# STM32H5F4 register map
File version: 1.0
CPU: CM33 r0p0, little endian, MPU, FPU, 4 interrupt priority bits
Registers are 32-bit, read-write, reset 0x0 unless marked. A register's access mark holds for its fields unless they carry their own. Offsets are from the block's base; [hi:lo] are bit positions; 'fields as' and 'values as' point back to an identical list.

## SAI1 — SAI1 register block
Base 0x40015400
Same registers: SAI2 0x40015800, SAI1_S 0x50015400, SAI2_S 0x50015800
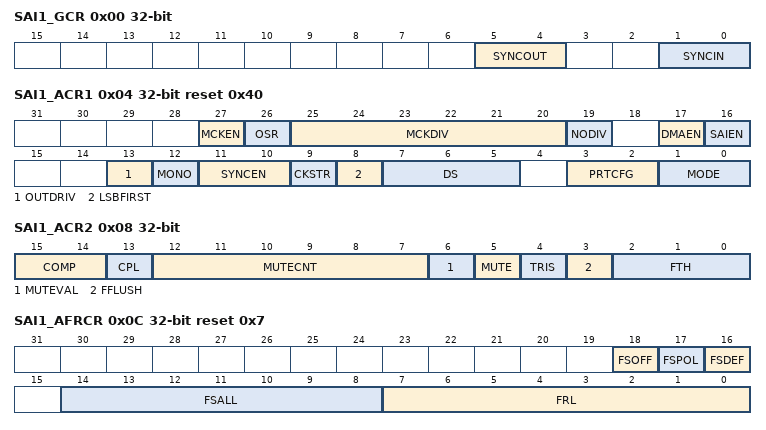
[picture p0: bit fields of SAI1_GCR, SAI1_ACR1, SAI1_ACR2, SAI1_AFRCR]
0x00 SAI1_GCR — SAI global configuration register
  [5:4] SYNCOUT — Synchronization outputs
    0=No synchronization output signals; 1=Block A used for further synchronization for others SAI; 2=Block B used for further synchronization for others SAI
  [1:0] SYNCIN — Synchronization inputs
0x04 SAI1_ACR1 reset 0x40 — SAI configuration register 1
  [27] MCKEN — Master clock generation enable
    0=The master clock is not generated; 1=The master clock is generated independently of SAIEN bit
  [26] OSR — Oversampling ratio for master clock
    0=Master clock frequency = Fless thansub>FSless than/sub> x 256; 1=Master clock frequency = Fless thansub>FSless than/sub> x 512
  [25:20] MCKDIV — Master clock divider
    0=Divides by 1 the kernel clock input (sai_x_ker_ck)
  [19] NODIV — No divider
    0=the ratio between the Master clock generator and frame synchronization is fixed to 256 or 512; 1=the ratio between the Master clock generator and frame synchronization depends on FRL[7:0]
  [17] DMAEN — DMA enable
    0=DMA disabled; 1=DMA enabled
  [16] SAIEN — Audio block enable
    0=SAI audio block disabled; 1=SAI audio block enabled
  [13] OUTDRIV — Output drive
    0=Audio block output driven when SAIEN is set; 1=Audio block output driven immediately after the setting of this bit
  [12] MONO — Mono mode
    0=Stereo mode; 1=Mono mode
  [11:10] SYNCEN — Synchronization enable
    0=audio subblock in asynchronous mode; 1=audio subblock is synchronous with the other internal audio subblock; 2=audio subblock is synchronous with an external SAI embedded peripheral
  [9] CKSTR — Clock strobing edge
    0=Signals generated by the SAI change on SCK rising edge, while signals received by the SAI are sampled on the SCK falling edge; 1=Signals generated by the SAI change on SCK falling edge, while signals received by the SAI are sampled on the SCK rising edge
  [8] LSBFIRST — Least significant bit first
    0=Data are transferred with MSB first; 1=Data are transferred with LSB first
  [7:5] DS — Data size
    2=8 bits; 3=10 bits; 4=16 bits; 5=20 bits; 6=24 bits; 7=32 bits
  [3:2] PRTCFG — Protocol configuration
    0=Free protocol; 1=SPDIF protocol; 2=AC'97 protocol
  [1:0] MODE — SAIx audio block mode
    0=Master transmitter; 1=Master receiver; 2=Slave transmitter; 3=Slave receiver
0x08 SAI1_ACR2 — SAI configuration register 2
  [15:14] COMP — Companding mode.
    0=No companding algorithm; 2=u-Law algorithm; 3=A-Law algorithm
  [13] CPL — Complement bit.
    0=1's complement representation; 1=2's complement representation
  [12:7] MUTECNT — Mute counter.
  [6] MUTEVAL — Mute value.
    0=Bit value 0 is sent during the mute mode; 1=Last values are sent during the mute mode
  [5] MUTE
    0=No mute mode; 1=Mute mode enabled
  [4] TRIS — Tristate management on data line.
    0=SD output line is still driven by the SAI when a slot is inactive; 1=SD output line is released (HI-Z) at the end of the last data bit of the last active slot if the next one is inactive
  [3] FFLUSH wo — FIFO flush.
    0=No FIFO flush; 1=FIFO flush
  [2:0] FTH — FIFO threshold.
    0=FIFO empty; 1=1/4 FIFO; 2=half FIFO; 3=3/4 FIFO; 4=FIFO full
0x0C SAI1_AFRCR reset 0x7 — SAI frame configuration register
  [18] FSOFF — Frame synchronization offset.
    0=FS is asserted on the first bit of the slot 0; 1=FS is asserted one bit before the first bit of the slot 0
  [17] FSPOL — Frame synchronization polarity.
    0=FS is active low (falling edge); 1=FS is active high (rising edge)
  [16] FSDEF ro — Frame synchronization definition.
    0=FS signal is a start frame signal; 1=FS signal is a start of frame signal + channel side identification
  [14:8] FSALL — Frame synchronization active level length.
  [7:0] FRL — Frame length.
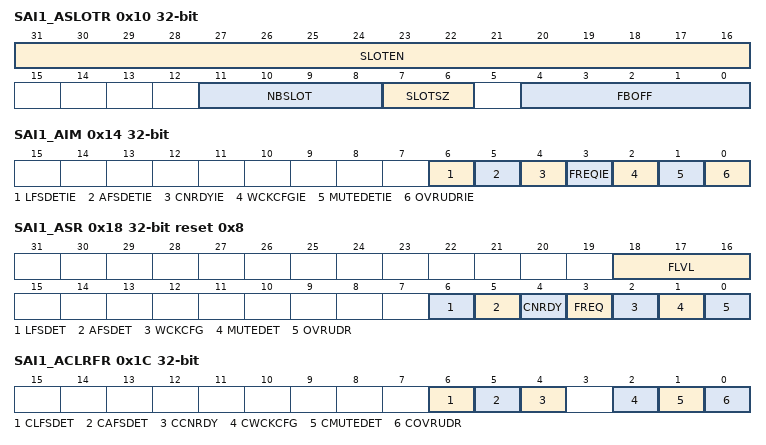
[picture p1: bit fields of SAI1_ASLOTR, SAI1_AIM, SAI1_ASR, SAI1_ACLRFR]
0x10 SAI1_ASLOTR — SAI slot register
  [31:16] SLOTEN — Slot enable.
    0=Inactive slot; 1=Active slot
  [11:8] NBSLOT — Number of slots in an audio frame.
  [7:6] SLOTSZ — Slot size
    0=The slot size is equivalent to the data size (specified in DS[3:0] in the SAI_xCR1 register); 1=16-bit; 2=32-bit
  [4:0] FBOFF — First bit offset
0x14 SAI1_AIM — SAI interrupt mask register
  [all] fields
    0=Interrupt is disabled; 1=Interrupt is enabled
  [6] LFSDETIE — Late frame synchronization detection interrupt enable.
  [5] AFSDETIE — Anticipated frame synchronization detection interrupt enable.
  [4] CNRDYIE — Codec not ready interrupt enable (AC'97).
  [3] FREQIE — FIFO request interrupt enable.
  [2] WCKCFGIE — Wrong clock configuration interrupt enable.
  [1] MUTEDETIE — Mute detection interrupt enable.
  [0] OVRUDRIE — Overrun/underrun interrupt enable.
0x18 SAI1_ASR ro reset 0x8 — SAI status register
  [18:16] FLVL — FIFO level threshold.
    0=FIFO empty (transmitter and receiver modes); 1=FIFO less than or equal 1/4 but not empty (transmitter mode), FIFO less than 1/4 but not empty (receiver mode); 2=1/4 less than FIFO less than or equal half (transmitter mode), 1/4 less than or equal FIFO less than half (receiver mode); 3=half less than FIFO less than or equal 3/4 (transmitter mode), half less than or equal FIFO less than 3/4 (receiver mode); 4=3/4 less than FIFO but not full (transmitter mode), 3/4 less than or equal FIFO but not full (receiver mode); 5=FIFO full (transmitter and receiver modes)
  [6] LFSDET — Late frame synchronization detection.
    0=No error; 1=Frame synchronization signal is not present at the right time
  [5] AFSDET — Anticipated frame synchronization detection.
    0=No error; 1=Frame synchronization signal is detected earlier than expected
  [4] CNRDY — Codec not ready.
    0=External AC'97 Codec is ready; 1=External AC'97 Codec is not ready
  [3] FREQ — FIFO request.
    0=No FIFO request; 1=FIFO request to read or to write the SAI_xDR
  [2] WCKCFG — Wrong clock configuration flag.
    0=Clock configuration is correct; 1=Clock configuration does not respect the rule concerning the frame length specification defined in Section63
  [1] MUTEDET — Mute detection.
    0=No MUTE detection on the SD input line; 1=MUTE value detected on the SD input line (0 value) for a specified number of consecutive audio frame
  [0] OVRUDR — Overrun / underrun.
    0=No overrun/underrun error; 1=Overrun/underrun error detection
0x1C SAI1_ACLRFR wo — SAI clear flag register
  [6] CLFSDET — Clear late frame synchronization detection flag.
  [5] CAFSDET — Clear anticipated frame synchronization detection flag.
  [4] CCNRDY — Clear Codec not ready flag.
  [2] CWCKCFG — Clear wrong clock configuration flag.
  [1] CMUTEDET — Mute detection flag.
  [0] COVRUDR — Clear overrun / underrun.
0x20 SAI1_ADR — SAI data register
  [31:0] DATA
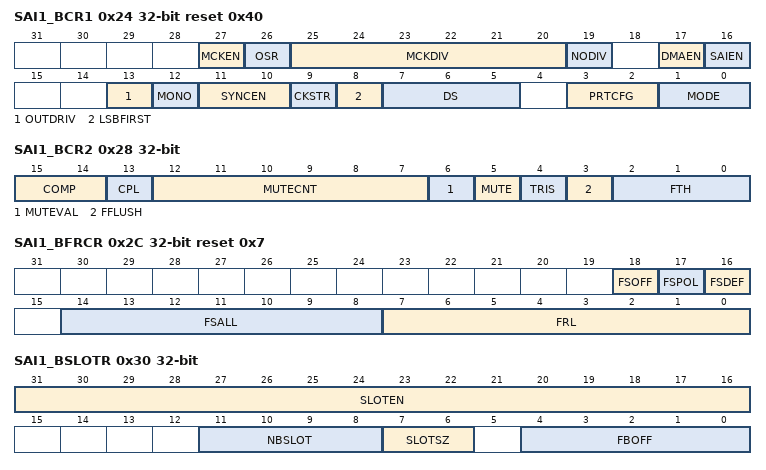
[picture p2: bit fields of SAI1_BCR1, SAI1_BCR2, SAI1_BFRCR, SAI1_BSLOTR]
0x24 SAI1_BCR1 reset 0x40 — SAI configuration register 1
  fields as SAI1_ACR1
0x28 SAI1_BCR2 — SAI configuration register 2
  fields as SAI1_ACR2
0x2C SAI1_BFRCR reset 0x7 — SAI frame configuration register
  fields as SAI1_AFRCR
0x30 SAI1_BSLOTR — SAI slot register
  fields as SAI1_ASLOTR
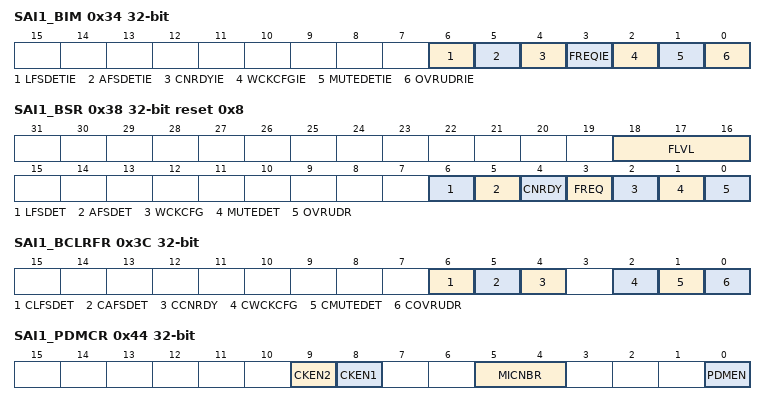
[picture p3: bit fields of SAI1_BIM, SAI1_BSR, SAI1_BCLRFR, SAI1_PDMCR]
0x34 SAI1_BIM — SAI interrupt mask register
  fields as SAI1_AIM
0x38 SAI1_BSR ro reset 0x8 — SAI status register
  fields as SAI1_ASR
0x3C SAI1_BCLRFR wo — SAI clear flag register
  fields as SAI1_ACLRFR
0x40 SAI1_BDR — SAI data register
  [31:0] DATA
0x44 SAI1_PDMCR — SAI PDM control register
  [9] CKEN2 — Clock enable of bitstream clock number 2
    0=SAI_CK2 clock disabled; 1=SAI_CK2 clock enabled
  [8] CKEN1 — Clock enable of bitstream clock number 1
    0=SAI_CK1 clock disabled; 1=SAI_CK1 clock enabled
  [5:4] MICNBR — Number of microphones
    0=Configuration with 2 microphones; 1=Configuration with 4 microphones; 2=Configuration with 6 microphones; 3=Configuration with 8 microphones
  [0] PDMEN — PDM enable
    0=PDM interface disabled; 1=PDM interface enabled
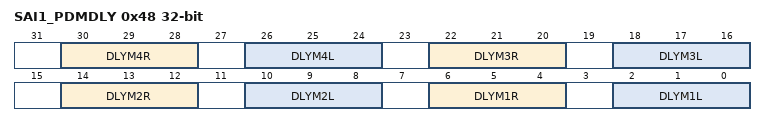
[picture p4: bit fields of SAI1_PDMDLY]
0x48 SAI1_PDMDLY — SAI PDM delay register
  [30:28] DLYM4R — Delay line for second microphone of pair 4
    0=No delay; 1=Delay of 1 Tless thansub>SAI_CK less than/sub>period; 2=Delay of 2 Tless thansub>SAI_CK less than/sub>periods; 7=Delay of 7 Tless thansub>SAI_CK less than/sub>periods
  [26:24] DLYM4L — Delay line for first microphone of pair 4
    0=No delay; 1=Delay of 1 Tless thansub>SAI_CK less than/sub>period; 2=Delay of 2 Tless thansub>SAI_CK less than/sub>periods; 7=Delay of 7 of Tless thansub>SAI_CK less than/sub>periods
  [22:20] DLYM3R — Delay line for second microphone of pair 3
    values as DLYM4R
  [18:16] DLYM3L — Delay line for first microphone of pair 3
    values as DLYM4R
  [14:12] DLYM2R — Delay line for second microphone of pair 2
    values as DLYM4R
  [10:8] DLYM2L — Delay line for first microphone of pair 2
    values as DLYM4R
  [6:4] DLYM1R — Delay line adjust for second microphone of pair 1
    values as DLYM4R
  [2:0] DLYM1L — Delay line adjust for first microphone of pair 1
    values as DLYM4R
